# PCIE0_CORE_PCIE_INTD_CFG_INTD_CFG register map
Vendor: Texas Instruments
Peripheral module from a debugger description file (folder J7ES).
Registers are 32-bit, access not given, reset values left out (the file's numbers can be read two ways) unless marked. A register's access mark holds for its fields unless they carry their own. Offsets are as the file gives them; lines under a group give offsets from that group; [hi:lo] are bit positions; {n}, {i} and the like mark numbered series; 'fields as' and 'values as' point back to an identical list; <NAME> marks a mode.

## PCIE0_CORE_PCIE_INTD_CFG_INTD_CFG
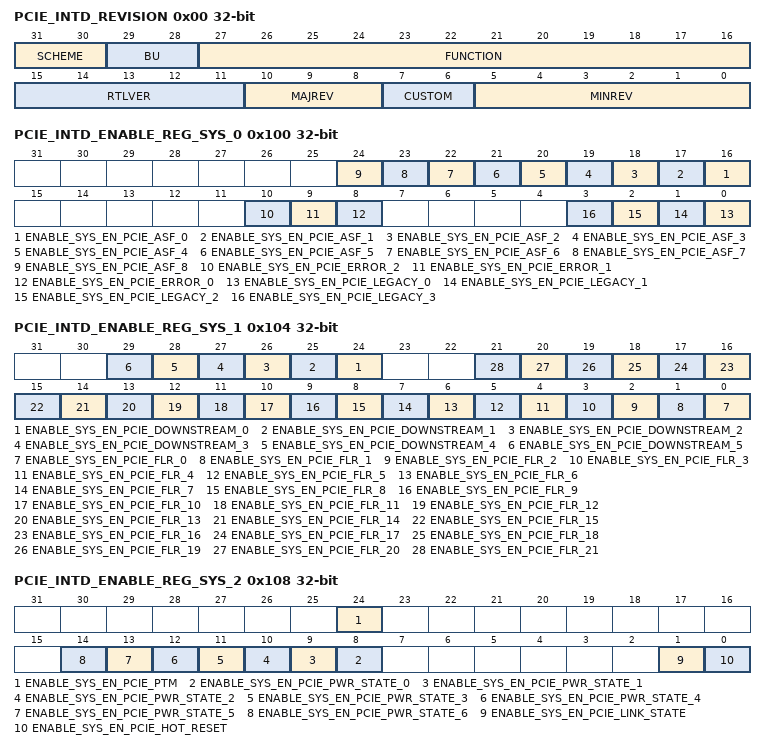
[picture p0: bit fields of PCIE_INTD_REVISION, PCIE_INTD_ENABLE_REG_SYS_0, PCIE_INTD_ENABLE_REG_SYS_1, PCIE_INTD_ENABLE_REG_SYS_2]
0x00 PCIE_INTD_REVISION ro — Register
  [31:30] SCHEME
  [29:28] BU
  [27:16] FUNCTION — Module ID
  [15:11] RTLVER — RTL revisions
  [10:8] MAJREV — Major
  [7:6] CUSTOM
  [5:0] MINREV — Minor
0x10 PCIE_INTD_EOI_REG rw — End of Interrupt Register
  [7:0] EOI_VECTOR — End of Interrupt Vector
0x14 PCIE_INTD_INTR_VECTOR_REG ro — Interrupt Vector Register
  [31:0] INTR_VECTOR
0x100 PCIE_INTD_ENABLE_REG_SYS_0 — Enable Register 0
  [n+16] ENABLE_SYS_EN_PCIE_ASF_{n} (n=0..8) — Enable Set for sys_en_pcie_asf_{n} (access RW1S)
  [10] ENABLE_SYS_EN_PCIE_ERROR_2 — Enable Set for sys_en_pcie_error_2 (access RW1S)
  [9] ENABLE_SYS_EN_PCIE_ERROR_1 — Enable Set for sys_en_pcie_error_1 (access RW1S)
  [8] ENABLE_SYS_EN_PCIE_ERROR_0 — Enable Set for sys_en_pcie_error_0 (access RW1S)
  [n] ENABLE_SYS_EN_PCIE_LEGACY_{n} (n=0..3) — Enable Set for sys_en_pcie_legacy_{n} (access RW1S)
0x104 PCIE_INTD_ENABLE_REG_SYS_1 — Enable Register 1
  [n+24] ENABLE_SYS_EN_PCIE_DOWNSTREAM_{n} (n=0..5) — Enable Set for sys_en_pcie_downstream_{n} (access RW1S)
  [n] ENABLE_SYS_EN_PCIE_FLR_{n} (n=0..21) — Enable Set for sys_en_pcie_flr_{n} (access RW1S)
0x108 PCIE_INTD_ENABLE_REG_SYS_2 — Enable Register 2
  [24] ENABLE_SYS_EN_PCIE_PTM — Enable Set for sys_en_pcie_ptm (access RW1S)
  [n+8] ENABLE_SYS_EN_PCIE_PWR_STATE_{n} (n=0..6) — Enable Set for sys_en_pcie_pwr_state_{n} (access RW1S)
  [1] ENABLE_SYS_EN_PCIE_LINK_STATE — Enable Set for sys_en_pcie_link_state (access RW1S)
  [0] ENABLE_SYS_EN_PCIE_HOT_RESET — Enable Set for sys_en_pcie_hot_reset (access RW1S)
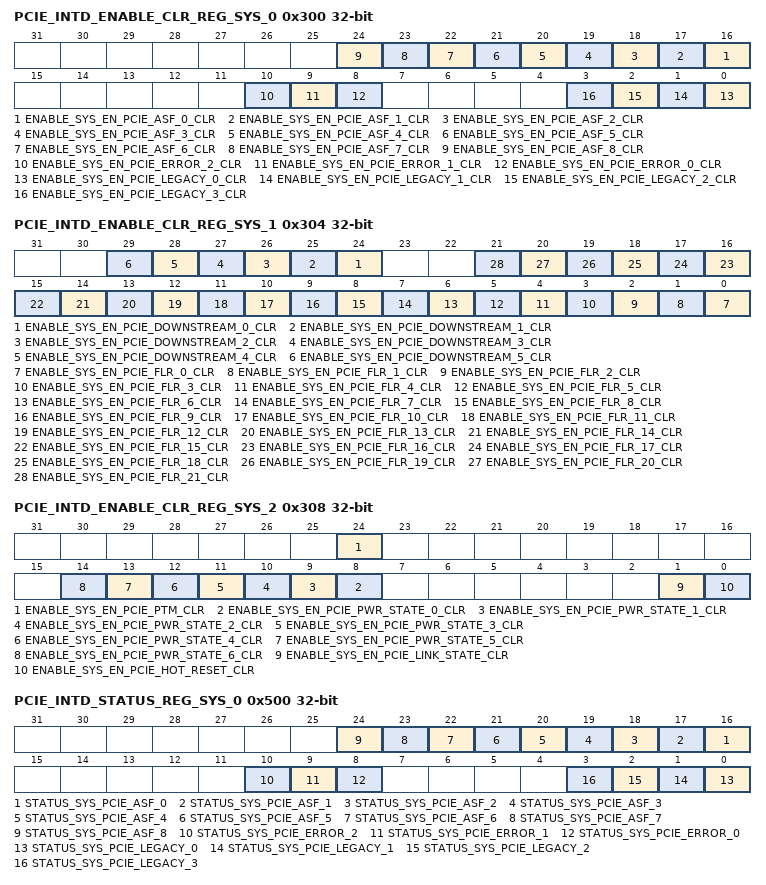
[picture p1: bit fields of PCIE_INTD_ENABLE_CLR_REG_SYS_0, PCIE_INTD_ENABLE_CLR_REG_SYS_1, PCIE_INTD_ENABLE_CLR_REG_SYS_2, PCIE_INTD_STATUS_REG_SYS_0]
0x300 PCIE_INTD_ENABLE_CLR_REG_SYS_0 — Enable Clear Register 0
  [n+16] ENABLE_SYS_EN_PCIE_ASF_{n}_CLR (n=0..8) — Enable Clear for sys_en_pcie_asf_{n} (access RW1C)
  [10] ENABLE_SYS_EN_PCIE_ERROR_2_CLR — Enable Clear for sys_en_pcie_error_2 (access RW1C)
  [9] ENABLE_SYS_EN_PCIE_ERROR_1_CLR — Enable Clear for sys_en_pcie_error_1 (access RW1C)
  [8] ENABLE_SYS_EN_PCIE_ERROR_0_CLR — Enable Clear for sys_en_pcie_error_0 (access RW1C)
  [n] ENABLE_SYS_EN_PCIE_LEGACY_{n}_CLR (n=0..3) — Enable Clear for sys_en_pcie_legacy_{n} (access RW1C)
0x304 PCIE_INTD_ENABLE_CLR_REG_SYS_1 — Enable Clear Register 1
  [n+24] ENABLE_SYS_EN_PCIE_DOWNSTREAM_{n}_CLR (n=0..5) — Enable Clear for sys_en_pcie_downstream_{n} (access RW1C)
  [n] ENABLE_SYS_EN_PCIE_FLR_{n}_CLR (n=0..21) — Enable Clear for sys_en_pcie_flr_{n} (access RW1C)
0x308 PCIE_INTD_ENABLE_CLR_REG_SYS_2 — Enable Clear Register 2
  [24] ENABLE_SYS_EN_PCIE_PTM_CLR — Enable Clear for sys_en_pcie_ptm (access RW1C)
  [n+8] ENABLE_SYS_EN_PCIE_PWR_STATE_{n}_CLR (n=0..6) — Enable Clear for sys_en_pcie_pwr_state_{n} (access RW1C)
  [1] ENABLE_SYS_EN_PCIE_LINK_STATE_CLR — Enable Clear for sys_en_pcie_link_state (access RW1C)
  [0] ENABLE_SYS_EN_PCIE_HOT_RESET_CLR — Enable Clear for sys_en_pcie_hot_reset (access RW1C)
0x500 PCIE_INTD_STATUS_REG_SYS_0 — Status Register 0
  [n+16] STATUS_SYS_PCIE_ASF_{n} (n=0..8) — Status ,write 1 to set, for sys_en_pcie_asf_{n} (access RW1S)
  [10] STATUS_SYS_PCIE_ERROR_2 — Status ,write 1 to set, for sys_en_pcie_error_2 (access RW1S)
  [9] STATUS_SYS_PCIE_ERROR_1 — Status ,write 1 to set, for sys_en_pcie_error_1 (access RW1S)
  [8] STATUS_SYS_PCIE_ERROR_0 — Status ,write 1 to set, for sys_en_pcie_error_0 (access RW1S)
  [n] STATUS_SYS_PCIE_LEGACY_{n} (n=0..3) — Status ,write 1 to set, for sys_en_pcie_legacy_{n} (access RW1S)
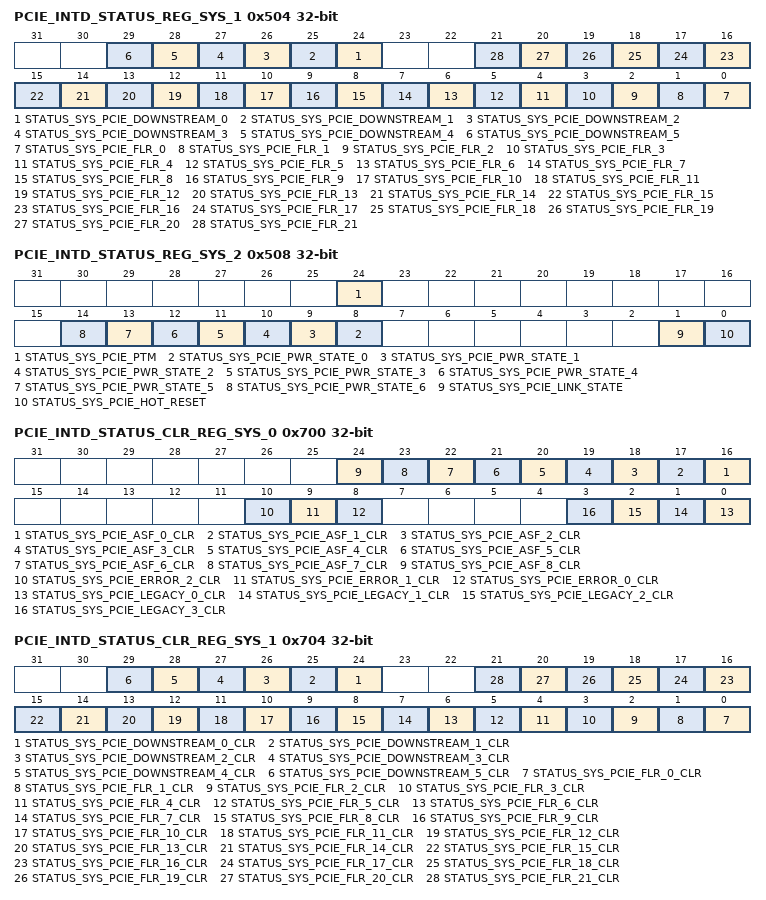
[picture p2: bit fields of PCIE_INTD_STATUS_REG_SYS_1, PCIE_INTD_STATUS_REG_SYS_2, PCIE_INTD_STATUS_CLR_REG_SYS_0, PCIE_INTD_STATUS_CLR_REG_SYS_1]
0x504 PCIE_INTD_STATUS_REG_SYS_1 — Status Register 1
  [n+24] STATUS_SYS_PCIE_DOWNSTREAM_{n} (n=0..5) — Status ,write 1 to set, for sys_en_pcie_downstream_{n} (access RW1S)
  [n] STATUS_SYS_PCIE_FLR_{n} (n=0..21) — Status ,write 1 to set, for sys_en_pcie_flr_{n} (access RW1S)
0x508 PCIE_INTD_STATUS_REG_SYS_2 — Status Register 2
  [24] STATUS_SYS_PCIE_PTM — Status ,write 1 to set, for sys_en_pcie_ptm (access RW1S)
  [n+8] STATUS_SYS_PCIE_PWR_STATE_{n} (n=0..6) — Status ,write 1 to set, for sys_en_pcie_pwr_state_{n} (access RW1S)
  [1] STATUS_SYS_PCIE_LINK_STATE — Status ,write 1 to set, for sys_en_pcie_link_state (access RW1S)
  [0] STATUS_SYS_PCIE_HOT_RESET — Status ,write 1 to set, for sys_en_pcie_hot_reset (access RW1S)
0x700 PCIE_INTD_STATUS_CLR_REG_SYS_0 — Status Clear Register 0
  [n+16] STATUS_SYS_PCIE_ASF_{n}_CLR (n=0..8) — Status ,write 1 to clear, for sys_en_pcie_asf_{n} (access RW1C)
  [10] STATUS_SYS_PCIE_ERROR_2_CLR — Status ,write 1 to clear, for sys_en_pcie_error_2 (access RW1C)
  [9] STATUS_SYS_PCIE_ERROR_1_CLR — Status ,write 1 to clear, for sys_en_pcie_error_1 (access RW1C)
  [8] STATUS_SYS_PCIE_ERROR_0_CLR — Status ,write 1 to clear, for sys_en_pcie_error_0 (access RW1C)
  [n] STATUS_SYS_PCIE_LEGACY_{n}_CLR (n=0..3) — Status ,write 1 to clear, for sys_en_pcie_legacy_{n} (access RW1C)
0x704 PCIE_INTD_STATUS_CLR_REG_SYS_1 — Status Clear Register 1
  [n+24] STATUS_SYS_PCIE_DOWNSTREAM_{n}_CLR (n=0..5) — Status ,write 1 to clear, for sys_en_pcie_downstream_{n} (access RW1C)
  [n] STATUS_SYS_PCIE_FLR_{n}_CLR (n=0..21) — Status ,write 1 to clear, for sys_en_pcie_flr_{n} (access RW1C)
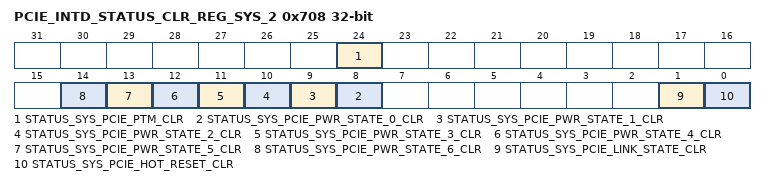
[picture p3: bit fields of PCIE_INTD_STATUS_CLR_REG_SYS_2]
0x708 PCIE_INTD_STATUS_CLR_REG_SYS_2 — Status Clear Register 2
  [24] STATUS_SYS_PCIE_PTM_CLR — Status ,write 1 to clear, for sys_en_pcie_ptm (access RW1C)
  [n+8] STATUS_SYS_PCIE_PWR_STATE_{n}_CLR (n=0..6) — Status ,write 1 to clear, for sys_en_pcie_pwr_state_{n} (access RW1C)
  [1] STATUS_SYS_PCIE_LINK_STATE_CLR — Status ,write 1 to clear, for sys_en_pcie_link_state (access RW1C)
  [0] STATUS_SYS_PCIE_HOT_RESET_CLR — Status ,write 1 to clear, for sys_en_pcie_hot_reset (access RW1C)
0xA80 PCIE_INTD_INTR_VECTOR_REG_SYS ro — Interrupt Vector for sys
  [31:0] INTR_VECTOR_SYS — Interrupt Vector
